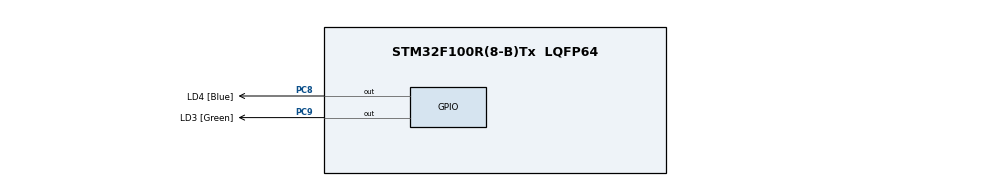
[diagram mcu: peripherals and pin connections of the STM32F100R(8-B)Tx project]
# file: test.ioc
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Mcu.Family=STM32F1
Mcu.Name=STM32F100R(8-B)Tx
Mcu.Package=LQFP64
NVIC.PriorityGroup=NVIC_PRIORITYGROUP_4
PA0-WKUP.Mode=SYS_WakeUp0
PA0-WKUP.Signal=SYS_WKUP
PA13.GPIO_Label=TMS_SWDIO
PA13.Mode=Serial_Wire
PA13.Signal=SYS_JTMS-SWDIO
PA14.GPIO_Label=TCK_SWCLK
PA14.Mode=Serial_Wire
PA14.Signal=SYS_JTCK-SWCLK
PC14-OSC32_IN.Mode=LSE-External-Oscillator
PC14-OSC32_IN.Signal=RCC_OSC32_IN
PC15-OSC32_OUT.Mode=LSE-External-Oscillator
PC15-OSC32_OUT.Signal=RCC_OSC32_OUT
PC8.GPIO_Label=LD4 [Blue]
PC8.Signal=GPIO_Output
PC9.GPIO_Label=LD3 [Green]
PC9.Signal=GPIO_Output
PD0-OSC_IN.Mode=HSE-External-Oscillator
PD0-OSC_IN.Signal=RCC_OSC_IN
PD1-OSC_OUT.Mode=HSE-External-Oscillator
PD1-OSC_OUT.Signal=RCC_OSC_OUT
ProjectManager.HeapSize=0x200
ProjectManager.StackSize=0x400
ProjectManager.TargetToolchain=Makefile
RCC.APB1Freq_Value=8000000
RCC.APB2Freq_Value=8000000
board=STM32VLDISCOVERY

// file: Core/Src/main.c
/* USER CODE BEGIN Header */
/**
  ******************************************************************************
  * @file           : main.c
  * @brief          : Main program body
  ******************************************************************************
  * @attention
  *
  * <h2><center>&copy; Copyright (c) 2023 STMicroelectronics.
  * All rights reserved.</center></h2>
  *
  * This software component is licensed by ST under BSD 3-Clause license,
  * the "License"; You may not use this file except in compliance with the
  * License. You may obtain a copy of the License at:
  *                        opensource.org/licenses/BSD-3-Clause
  *
  ******************************************************************************
  */
/* USER CODE END Header */
#include "main.h"

#include <stdio.h>
#include "tm1637_drv.h"
#include "rtc_drv.h"
#include "clock.h"
#include "USART.h"

void SystemClock_Config(void);
/* USER CODE BEGIN PFP */
void delay(int n);

/* USER CODE END PFP */

//uint32_t source6 = GPIO_BSRR_BS8 | GPIO_BSRR_BR9;
//uint32_t source7 = GPIO_BSRR_BR8 | GPIO_BSRR_BS9;

//#define DELAY 100
int main(void)
{

  /* MCU Configuration--------------------------------------------------------*/

  /* Reset of all peripherals, Initializes the Flash interface and the Systick. */
//  HAL_Init();

  /* Configure the system clock */
  SystemClock_Config();

  /* USER CODE BEGIN 2 */
//    __HAL_RCC_GPIOC_CLK_ENABLE();
    __HAL_RCC_GPIOD_CLK_ENABLE();
    __HAL_RCC_GPIOA_CLK_ENABLE();
//
//    RCC->APB2RSTR |= 1U << 4U;
//    RCC->APB2RSTR &= ~(1U << 4U);
//
//    GPIOC->CRH &= ~GPIO_CRH_MODE9_Msk;
//    GPIOC->CRH |= 2U << GPIO_CRH_MODE9_Pos ;
//    GPIOC->CRH &= ~(3U << GPIO_CRH_CNF9_Pos);
//
//    GPIOC->CRH &= ~(GPIO_CRH_MODE8_Msk);
//    GPIOC->CRH |= GPIO_CRH_MODE8_1;
//    GPIOC->CRH &= ~(3U << GPIO_CRH_CNF8_Pos);

//    RCC->APB1ENR |= RCC_APB1ENR_TIM7EN;

//    TIM7->DIER |= 1U << 0U;
//    TIM7->PSC = 399U;
//    uint32_t freq = HAL_RCC_GetSysClockFreq();
//    uint16_t period = freq / 8000U;
//    TIM7->ARR = period;
//    TIM7->CR1 |= 1U << 0U;
//    HAL_NVIC_EnableIRQ(TIM7_IRQn);
//    HAL_NVIC_EnableIRQ(DMA1_Channel6_IRQn);
//    HAL_NVIC_EnableIRQ(DMA1_Channel7_IRQn);

//    RCC->APB1ENR |= RCC_APB1ENR_TIM3EN;
//
//    TIM3->PSC = 399U;
//    TIM3->ARR = period;
//    TIM3->CCR3 = 9 * period / 10;
//    TIM3->CCR4 = 9 * period / 10;
//    TIM3->CCMR2 = TIM_CCMR2_OC3M_1 | TIM_CCMR2_OC3M_2 | TIM_CCMR2_OC4M_1 | TIM_CCMR2_OC4M_2;
//    TIM3->CCER = TIM_CCER_CC3E | TIM_CCER_CC4P | TIM_CCER_CC4E;
//    TIM3->CR1 |= 1U << 0U;
//
//    AFIO->MAPR |= AFIO_MAPR_TIM3_REMAP;
//
//    GPIOC->CRH |= GPIO_CRH_MODE8 | GPIO_CRH_CNF8_1 | GPIO_CRH_MODE9 | GPIO_CRH_CNF9_1;

//    RCC->APB2ENR |= RCC_APB2ENR_TIM16EN;
//    RCC->APB2ENR |= RCC_APB2ENR_TIM17EN;
//    RCC->AHBENR |= RCC_AHBENR_DMA1EN;
//
//
//
//
//    DMA1_Channel6->CMAR = (uint32_t) &source6;
//    DMA1_Channel7->CMAR = (uint32_t) &source7;
//
//    DMA1_Channel6->CNDTR = 1U;
//    DMA1_Channel7->CNDTR = 1U;
//    DMA1_Channel6->CPAR = (uint32_t) &GPIOC->BSRR;
//    DMA1_Channel7->CPAR = (uint32_t) &GPIOC->BSRR;
//    DMA1_Channel6->CCR = DMA_CCR_MSIZE_1 | DMA_CCR_PSIZE_1 | DMA_CCR_DIR
//            | DMA_CCR_TCIE | DMA_CCR_EN | DMA_CCR_CIRC;
//    DMA1_Channel7->CCR = DMA_CCR_MSIZE_1 | DMA_CCR_PSIZE_1 | DMA_CCR_DIR
//            | DMA_CCR_TCIE | DMA_CCR_EN  | DMA_CCR_CIRC;
//
//    TIM16->PSC = 399U;
//    TIM17->PSC = 399U;
//    TIM16->ARR = period * 4 / 15;
//    TIM17->ARR = period * 4 / 14;
//    TIM16->DIER |= TIM_DIER_UDE;
//    TIM17->DIER |= TIM_DIER_UDE;
//    TIM16->CR1 |= TIM_CR1_CEN;
//    TIM17->CR1 |= TIM_CR1_CEN;

//    RCC->APB1ENR |= RCC_APB1ENR_TIM7EN;
//    TIM7->ARR = period;
//    TIM7->DIER = TIM_DIER_UIE;
//    HAL_NVIC_EnableIRQ(TIM7_IRQn);
//
//    GPIOC->CRH = GPIO_CRH_MODE13_0 | GPIO_CRH_MODE8_0;
//    GPIOC->ODR = GPIO_ODR_ODR13 | GPIO_ODR_ODR8;
//
//    delay(DELAY);

    clock_init();
    init_usart1();

  /* USER CODE END 2 */

  /* Infinite loop */
  while (1)
  {

  }
}

void delay(int n) {
    for (; n>0; n--);
}

void SystemClock_Config(void)
{
  RCC_OscInitTypeDef RCC_OscInitStruct = {0};
  RCC_ClkInitTypeDef RCC_ClkInitStruct = {0};

  /** Initializes the RCC Oscillators according to the specified parameters
  * in the RCC_OscInitTypeDef structure.
  */
  RCC_OscInitStruct.OscillatorType = RCC_OSCILLATORTYPE_HSI;
  RCC_OscInitStruct.HSIState = RCC_HSI_ON;
  RCC_OscInitStruct.HSICalibrationValue = RCC_HSICALIBRATION_DEFAULT;
  RCC_OscInitStruct.PLL.PLLState = RCC_PLL_NONE;
  if (HAL_RCC_OscConfig(&RCC_OscInitStruct) != HAL_OK)
  {
    Error_Handler();
  }
  /** Initializes the CPU, AHB and APB buses clocks
  */
  RCC_ClkInitStruct.ClockType = RCC_CLOCKTYPE_HCLK|RCC_CLOCKTYPE_SYSCLK
                              |RCC_CLOCKTYPE_PCLK1|RCC_CLOCKTYPE_PCLK2;
  RCC_ClkInitStruct.SYSCLKSource = RCC_SYSCLKSOURCE_HSI;
  RCC_ClkInitStruct.AHBCLKDivider = RCC_SYSCLK_DIV1;
  RCC_ClkInitStruct.APB1CLKDivider = RCC_HCLK_DIV1;
  RCC_ClkInitStruct.APB2CLKDivider = RCC_HCLK_DIV1;

  if (HAL_RCC_ClockConfig(&RCC_ClkInitStruct, FLASH_LATENCY_0) != HAL_OK)
  {
    Error_Handler();
  }
}

/* USER CODE BEGIN 4 */

void DMA1_Channel6_IRQHandler(void) {
    DMA1->IFCR = DMA_IFCR_CGIF6;
}

void DMA1_Channel7_IRQHandler(void) {
    DMA1->IFCR = DMA_IFCR_CGIF7;
}

/* USER CODE END 4 */

void Error_Handler(void)
{
  __disable_irq();
  while (1)
  {
  }
}

/************************ (C) COPYRIGHT STMicroelectronics *****END OF FILE****/
